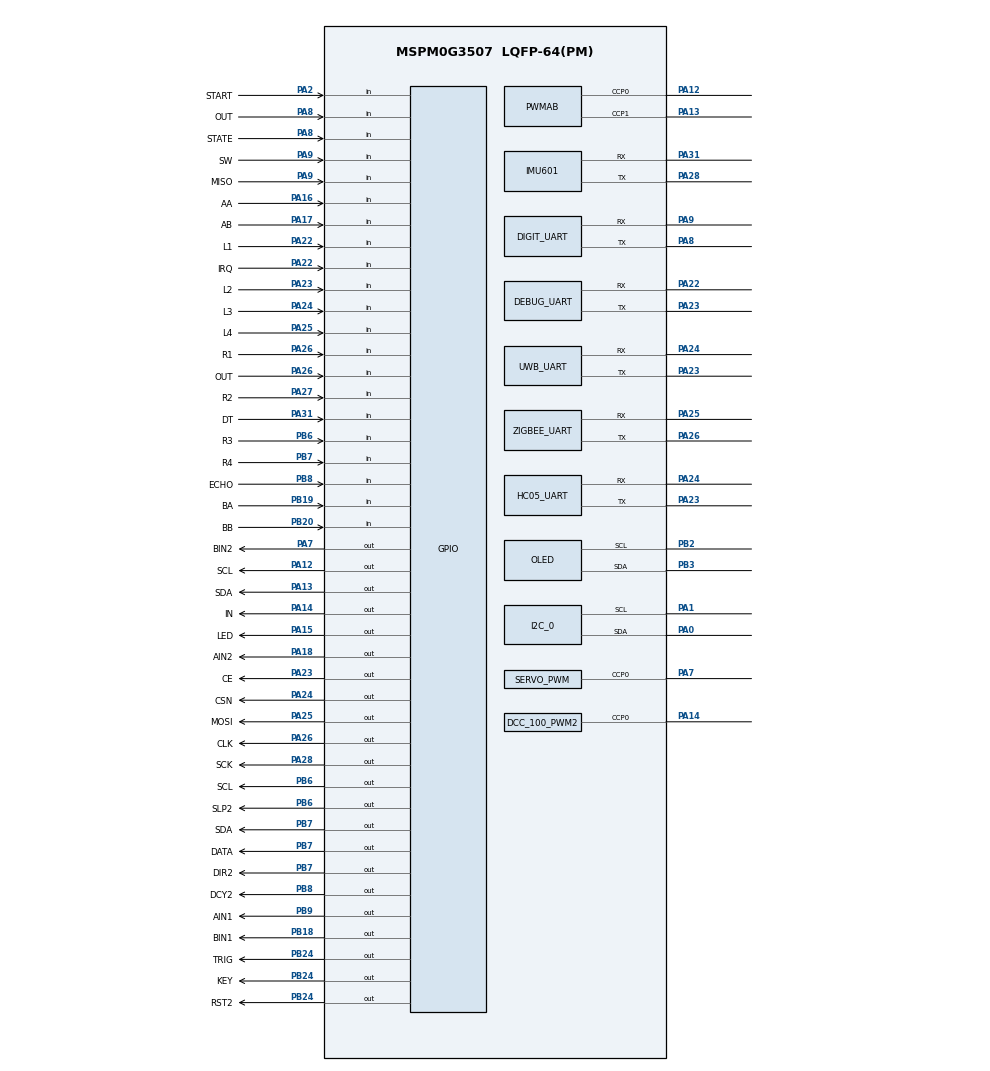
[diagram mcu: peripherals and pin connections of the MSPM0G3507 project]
/**
 * firstep mspm0 母版默认外设布局（地猛星 LCKFB-DMX 开发板，模块库默认引脚方案，
 * 编译闭环用；2026-08-14 地猛星化，工单 mspm0-master-dimx/01）。
 * 实例名/宏名与模块库代码一一对应（PWMAB/DC_MOTOR/IMU601/OLED/NTB/MOTOR_PID/
 * HUIDU/KEY/LED_BEEP/STEP_MOTOR/DCC_100_PWM2/I2C_0）；实际接线不同时改引脚名
 * 即可，实例名与宏名勿动。
 * 引脚方案（除 PB4/PB5 外全部在地猛星 2×20 排针上）：
 *   motor：PWMAB C0/C1→PA12/PA13、DC_MOTOR AIN1=PB9 AIN2=PA18 BIN1=PB18
 *   BIN2=PA7、编码器 AA=PA16 AB=PA17 BA=PB19 BB=PB20
 *   HUIDU：PA22-27/PB4/PB5（R3/R4 的 PB4/PB5 为 LaunchPad 遗留，地猛星未引出）
 *   KEY：PA2（板载 ROSC 偏置 100k 到地，按键与上拉共用此脚）
 *   LED_BEEP：PA15；IR_BEAM：PA8（红外对射 OUT，ir_beam 模块；与
 *   DIGIT_UART 默认重叠，同选时经引脚绑定消解）；IMU601：UART0 =
 *   PA28(TX)/PA31(RX)（板载 CH340E 占
 *   UART0 的 PA10/PA11，勿用）；DIGIT_UART：UART1 = PA8(TX)/PA9(RX)（K230 串口）
 *   OLED：I2C1 = PB3(SDA)/PB2(SCL)；I2C_0：I2C0 = PA0(SDA)/PA1(SCL)（MPU6050，
 *   复用板载 LED 脚——总线空闲高电平 LED 不亮，通信期间微闪；PA1 板载 4.7k 上拉，
 *   PA0 上拉未焊 R12，靠 MPU 板自带）
 *   STEP_MOTOR：RST2/SLP2/DIR2/DCY2 = PB24/PB6/PB7/PB8（全 GPIOB，
 *   STEP_MOTOR_PORT 整组 GPIOB）；DCC_100_PWM2：TIMG12 C0 = PA14（板上经
 *   LED2+15k 到地，PWM 输出时 LED 微亮，可忽略）
 *   JOYSTICK：SW = PA9（摇杆按键，上拉输入低有效；与 DIGIT_UART RX 默认
 *   重叠——手动摇杆与 K230 视觉同选概率最低，同选时经引脚绑定消解）；
 *   ADC12_0 四通道：MEM0 = PA24(A0_3) 归 adc 模块（us016 共读同槽），
 *   MEM1 = PA26(A0_1) / MEM2 = PA25(A0_2) 归 joystick 摇杆 X/Y（与
 *   ZIGBEE_UART 默认重叠——手动摇杆与无线身份/信标同选概率最低，同选时
 *   经引脚绑定消解；多 MEM 必须 sequence 模式，2026-09-05 SysConfig CLI
 *   实证），MEM3 = PA27(A0_0) 归 ir_distance（与 HUIDU R2 重叠——红外
 *   测距与灰度巡线同选概率最低）
 *   HC05：HC05_UART = UART2 共享（9600——HC05 出厂默认波特率，与 DEBUG+UWB
 *   同外设；默认 PA23/PA24 与 UWB 同脚——蓝牙与 UWB 链路互替、同选概率
 *   最低，同选时经引脚绑定换实例消解）；STATE = PA8 输入（连接状态，
 *   高有效；与 DIGIT_UART TX/IR_BEAM OUT 重叠——蓝牙与 K230 视觉/红外对射
 *   链路互替）、KEY = PB24 输出（AT 模式切换，与 STEP_MOTOR RST2/SR04 TRIG
 *   重叠——AT 切换不常用，同选经引脚绑定消解）
 *   NRF24L01：软 SPI 6 脚全 GPIOA（CLK=PA26/MOSI=PA25/MISO=PA9/
 *   CSN=PA24/CE=PA23/IRQ=PA22，单 NRF24L01_PORT 宏）——与 ZIGBEE_UART/
 *   UWB/DEBUG_UART/HUIDU 巡线/joystick/adc/DIGIT 默认重叠：NRF 与其它无线
 *   链路互替、同选概率最低，同选时经引脚绑定消解；IRQ 输入不配中断（GPIO
 *   中断只有 GROUP1 一路且被 motor 编码器独占，第二个 GROUP1_IRQHandler 会
 *   链接期冲突——按手册轮询方式接收，见 nrf24l01 模块注释）
 *   IR_REMOTE：OUT = PA26 输入（红外接收头，NEC 忙等解码不占 TIMER；
 *   与 ZIGBEE_TX/joystick X/NRF24L01 CLK 重叠——红外与其它无线/手动输入
 *   互替、同选概率最低，同选时经引脚绑定消解；主循环轮询解码，不注册
 *   GPIO 中断，原因同 NRF24L01）
 * 板上固定占用：CH340E PA10/PA11、Flash PB14-17、晶振 PA3-6、板载 LED PA0/PA1、
 * VREF- PA21 直连地、BSL PA18（47k 到 BSL 排针）、SWD PA19/PA20（独立 DEBUG 排针，
 * 用户实物未在 2×20P 上找到 A19/A20）、NRST。2026-08-20 用户实物核验：芯片丝印
 * 可见 42WG4 / ABDL，外周为 48 脚，2×20P 排针分布正确，PA13/PA14 在排针上可用。
 * TI 封装命名中 LQFP(PT)=48 脚、LQFP(PM)=64 脚；当前 SysConfig 仍沿用可工作的
 * LQFP-64(PM) / LP-MSPM0G3507 模型，不以此反推实物脚数。实际地猛星 2×20P
 * 引出范围由 mspm0-dimx 板定义约束，PB4/PB5 为 LaunchPad 遗留模型脚、不在 2×20P 上。
 */
//@cliArgs --device "MSPM0G350X" --package "LQFP-64(PM)" --part "Default"
//@v2CliArgs --device "MSPM0G3507" --package "LQFP-64(PM)"
// @cliArgs --board /ti/boards/LP_MSPM0G3507 --rtos nortos

/**
 * Import the modules used in this configuration.
 */
const PWM     = scripting.addModule("/ti/driverlib/PWM", {}, false);
const PWMAB   = PWM.addInstance();
const DCC_100_PWM2 = PWM.addInstance();
// 舵机（servo 模块：50Hz/20ms 周期，0.5-2.5ms 脉宽映射 0-180°；周期由
// servo_init 按 SERVO_PWM_INST_CLK_FREQ 运行时配置，此处初值仅保证可编译）
const SERVO_PWM = PWM.addInstance();
SERVO_PWM.$name                      = "SERVO_PWM";
SERVO_PWM.clockPrescale              = 1;
SERVO_PWM.timerCount                 = 65535;
SERVO_PWM.peripheral.$assign         = "TIMG8";
SERVO_PWM.peripheral.ccp0Pin.$assign = "PA7";
const TIMER   = scripting.addModule("/ti/driverlib/TIMER", {}, false);
const MOTOR_PID = TIMER.addInstance();
const NTB     = TIMER.addInstance();
const GPIO    = scripting.addModule("/ti/driverlib/GPIO", {}, false);
const DC_MOTOR = GPIO.addInstance();
const HUIDU   = GPIO.addInstance();
const KEY     = GPIO.addInstance();
const WS2812 = GPIO.addInstance();
const HX711 = GPIO.addInstance();
const AHT10 = GPIO.addInstance();
const SR04 = GPIO.addInstance();
const JOYSTICK = GPIO.addInstance();
const HC05 = GPIO.addInstance();
const NRF24L01 = GPIO.addInstance();
const IR_REMOTE = GPIO.addInstance();
const LED_BEEP = GPIO.addInstance();
const STEP_MOTOR = GPIO.addInstance();
const IR_BEAM = GPIO.addInstance();
const UART    = scripting.addModule("/ti/driverlib/UART", {}, false);
const IMU601  = UART.addInstance();
const I2C     = scripting.addModule("/ti/driverlib/I2C", {}, false);
const OLED    = I2C.addInstance();
const I2C_0   = I2C.addInstance();
const SYSCTL  = scripting.addModule("/ti/driverlib/SYSCTL");

/**
 * Write custom configuration values to the imported modules.
 */

// 电机 PWM：双通道 C0/C1（TB6612 左/右 PWM 输入）
PWMAB.$name                      = "PWMAB";
PWMAB.clockPrescale              = 256;
PWMAB.timerCount                 = 2000;
PWMAB.peripheral.$assign         = "TIMG0";
PWMAB.peripheral.ccp0Pin.$assign = "PA12";
PWMAB.peripheral.ccp1Pin.$assign = "PA13";
PWMAB.PWM_CHANNEL_0.$name        = "ti_driverlib_pwm_PWMTimerCC0";
PWMAB.PWM_CHANNEL_0.dutyCycle    = 0;
PWMAB.PWM_CHANNEL_1.$name        = "ti_driverlib_pwm_PWMTimerCC1";
PWMAB.PWM_CHANNEL_1.dutyCycle    = 0;

// 步进电机脉冲输出（step_motor 模块：DCC_100_PWM2_INST，TIMG12 32 位定时器，
// clockPrescale 必须为 1——step_set_speed 按 INST_CLK_FREQ/频率 直算周期；C0 = PA14）
DCC_100_PWM2.$name              = "DCC_100_PWM2";
DCC_100_PWM2.clockPrescale      = 1;
DCC_100_PWM2.timerCount         = 65535;
DCC_100_PWM2.peripheral.$assign = "TIMG12";
DCC_100_PWM2.peripheral.ccp0Pin.$assign = "PA14";
DCC_100_PWM2.PWM_CHANNEL_0.$name        = "ti_driverlib_pwm_DCC100_CC0";
DCC_100_PWM2.PWM_CHANNEL_0.dutyCycle    = 50;

// 电机 PID 调度定时器（10ms 周期中断，pid 模块用；编译闭环只需宏存在）
MOTOR_PID.$name              = "MOTOR_PID";
MOTOR_PID.profile            = "Basic_Periodic";
MOTOR_PID.peripheral.$assign = "TIMG6";

// 计程定时器（ntb_time 模块读计数）
NTB.$name              = "NTB";
NTB.profile            = "Basic_Periodic";
NTB.peripheral.$assign = "TIMG7";

// 超声波 TRIG/ECHO（sr04 模块：TRIG 输出触发 / ECHO 输入回波；测宽用
// CPU 忙等计数，不占 TIMER 外设——地猛星 SysConfig TIMER 实例仅暴露
// TIMG0/6/7/8/12（已被 motor/pid/ntb_time/servo/step_motor 全占，没有
// 新定时器可加）。默认 TRIG=PB24（与 STEP_MOTOR RST2 重叠）、ECHO=PB8
// （与 STEP_MOTOR DCY2 重叠）——测距与步进同选概率最低，同选时经引脚
// 绑定消解）
SR04.$name = "SR04";
SR04.associatedPins.create(2);
SR04.associatedPins[0].$name        = "TRIG";
SR04.associatedPins[0].direction    = "OUTPUT";
SR04.associatedPins[0].initialValue = "CLEARED";
SR04.associatedPins[0].pin.$assign  = "PB24";
SR04.associatedPins[1].$name        = "ECHO";
SR04.associatedPins[1].direction    = "INPUT";
SR04.associatedPins[1].pin.$assign  = "PB8";

// 电机方向/使能 + 编码器中断（key 模块 GROUP1_IRQHandler 消费 IIDX）
DC_MOTOR.$name = "DC_MOTOR";
DC_MOTOR.associatedPins.create(8);
DC_MOTOR.associatedPins[0].$name        = "AIN1";
DC_MOTOR.associatedPins[0].direction    = "OUTPUT";
DC_MOTOR.associatedPins[0].initialValue = "CLEARED";
DC_MOTOR.associatedPins[0].pin.$assign  = "PB9";
DC_MOTOR.associatedPins[1].$name        = "AIN2";
DC_MOTOR.associatedPins[1].direction    = "OUTPUT";
DC_MOTOR.associatedPins[1].initialValue = "CLEARED";
DC_MOTOR.associatedPins[1].pin.$assign  = "PA18";
DC_MOTOR.associatedPins[2].$name        = "BIN1";
DC_MOTOR.associatedPins[2].direction    = "OUTPUT";
DC_MOTOR.associatedPins[2].initialValue = "CLEARED";
DC_MOTOR.associatedPins[2].pin.$assign  = "PB18";
DC_MOTOR.associatedPins[3].$name        = "BIN2";
DC_MOTOR.associatedPins[3].direction    = "OUTPUT";
DC_MOTOR.associatedPins[3].initialValue = "CLEARED";
DC_MOTOR.associatedPins[3].pin.$assign  = "PA7";
DC_MOTOR.associatedPins[4].$name        = "AA";
DC_MOTOR.associatedPins[4].direction    = "INPUT";
DC_MOTOR.associatedPins[4].interruptEn  = true;
DC_MOTOR.associatedPins[4].polarity     = "RISE_FALL";
DC_MOTOR.associatedPins[4].pin.$assign  = "PA16";
DC_MOTOR.associatedPins[5].$name        = "AB";
DC_MOTOR.associatedPins[5].direction    = "INPUT";
DC_MOTOR.associatedPins[5].interruptEn  = true;
DC_MOTOR.associatedPins[5].polarity     = "RISE_FALL";
DC_MOTOR.associatedPins[5].pin.$assign  = "PA17";
DC_MOTOR.associatedPins[6].$name        = "BA";
DC_MOTOR.associatedPins[6].direction    = "INPUT";
DC_MOTOR.associatedPins[6].interruptEn  = true;
DC_MOTOR.associatedPins[6].polarity     = "RISE_FALL";
DC_MOTOR.associatedPins[6].pin.$assign  = "PB19";
DC_MOTOR.associatedPins[7].$name        = "BB";
DC_MOTOR.associatedPins[7].direction    = "INPUT";
DC_MOTOR.associatedPins[7].interruptEn  = true;
DC_MOTOR.associatedPins[7].polarity     = "RISE_FALL";
DC_MOTOR.associatedPins[7].pin.$assign  = "PB20";

// 8 路灰度循线输入（引脚空闲位，按实际接线改）
HUIDU.$name = "HUIDU";
HUIDU.associatedPins.create(8);
HUIDU.associatedPins[0].$name       = "L1";
HUIDU.associatedPins[0].direction   = "INPUT";
HUIDU.associatedPins[0].pin.$assign = "PA22";
HUIDU.associatedPins[1].$name       = "L2";
HUIDU.associatedPins[1].direction   = "INPUT";
HUIDU.associatedPins[1].pin.$assign = "PA23";
HUIDU.associatedPins[2].$name       = "L3";
HUIDU.associatedPins[2].direction   = "INPUT";
HUIDU.associatedPins[2].pin.$assign = "PA24";
HUIDU.associatedPins[3].$name       = "L4";
HUIDU.associatedPins[3].direction   = "INPUT";
HUIDU.associatedPins[3].pin.$assign = "PA25";
HUIDU.associatedPins[4].$name       = "R1";
HUIDU.associatedPins[4].direction   = "INPUT";
HUIDU.associatedPins[4].pin.$assign = "PA26";
HUIDU.associatedPins[5].$name       = "R2";
HUIDU.associatedPins[5].direction   = "INPUT";
HUIDU.associatedPins[5].pin.$assign = "PA27";
HUIDU.associatedPins[6].$name       = "R3";
HUIDU.associatedPins[6].direction   = "INPUT";
HUIDU.associatedPins[6].pin.$assign = "PB6";
HUIDU.associatedPins[7].$name       = "R4";
HUIDU.associatedPins[7].direction   = "INPUT";
HUIDU.associatedPins[7].pin.$assign = "PB7";

// 启动按键输入（实例名 KEY → KEY_PORT 宏；引脚名 START → KEY_START_PIN）
KEY.$name = "KEY";
KEY.associatedPins.create(1);
KEY.associatedPins[0].$name       = "START";
KEY.associatedPins[0].direction   = "INPUT";
KEY.associatedPins[0].pin.$assign = "PA2";

// 红外对射传感器输入（ir_beam 模块：实例名 IR_BEAM → IR_BEAM_PORT 宏；
// 引脚名 OUT → IR_BEAM_OUT_PIN；默认 PA8——仅与 DIGIT_UART 默认重叠，
// 同选时经引脚绑定消解；内部上拉 = 遮挡（开集输出截止）时由电阻钳到高，
// 无遮挡 = 接收管导通拉低）
IR_BEAM.$name = "IR_BEAM";
IR_BEAM.associatedPins.create(1);
IR_BEAM.associatedPins[0].$name            = "OUT";
IR_BEAM.associatedPins[0].direction        = "INPUT";
IR_BEAM.associatedPins[0].internalResistor = "PULL_UP";
IR_BEAM.associatedPins[0].pin.$assign      = "PA8";

// WS2812 幻彩灯带数据脚（ws2812 模块：单 GPIO 强推挽输出，位操作时序；
// 默认 PA14——与 DCC_100_PWM2（step_motor 脉冲）默认重叠，同选时经引脚
// 绑定消解。地猛星 2×20 排针 31 个 IO 已被母版默认布局全占，新模块默认
// 脚按「与同选概率最低者重叠」分配，IR_BEAM/PA8 先例）
WS2812.$name = "WS2812";
WS2812.associatedPins.create(1);
WS2812.associatedPins[0].$name        = "IN";
WS2812.associatedPins[0].direction    = "OUTPUT";
WS2812.associatedPins[0].initialValue = "CLEARED";
WS2812.associatedPins[0].pin.$assign  = "PA14";

// HX711 称重（hx711 模块：SCK 输出 / DT 输入（片上拉，空闲高 = 未就绪，
// 数据就绪拉低）。默认 SCK=PA28（与 IMU601 TX 重叠）、DT=PA31（与 IMU601
// RX 重叠）——称重与串口陀螺仪同为「姿态/力」低频组合，同选概率最低；
// 同选时经引脚绑定消解）
HX711.$name = "HX711";
HX711.associatedPins.create(2);
HX711.associatedPins[0].$name        = "SCK";
HX711.associatedPins[0].direction    = "OUTPUT";
HX711.associatedPins[0].initialValue = "CLEARED";
HX711.associatedPins[0].pin.$assign  = "PA28";
HX711.associatedPins[1].$name        = "DT";
HX711.associatedPins[1].direction    = "INPUT";
HX711.associatedPins[1].internalResistor = "PULL_UP";
HX711.associatedPins[1].pin.$assign  = "PA31";

// AHT10 温湿度软 I2C（aht10 模块：SCL 输出 / SDA 双向运行时切换；
// 位操作不占硬件 I2C 外设。默认 SCL=PB6（与 STEP_MOTOR SLP2 / HUIDU R3
// 重叠）、SDA=PB7（与 STEP_MOTOR DIR2 / HUIDU R4 重叠）——温湿度与步进/
// 巡线同选概率最低，同选时经引脚绑定消解；软 I2C 需板上/模块自带上拉）
AHT10.$name = "AHT10";
AHT10.associatedPins.create(2);
AHT10.associatedPins[0].$name        = "SCL";
AHT10.associatedPins[0].direction    = "OUTPUT";
AHT10.associatedPins[0].initialValue = "CLEARED";
AHT10.associatedPins[0].pin.$assign  = "PB6";
AHT10.associatedPins[1].$name        = "SDA";
AHT10.associatedPins[1].direction    = "OUTPUT";
AHT10.associatedPins[1].initialValue = "CLEARED";
AHT10.associatedPins[1].pin.$assign  = "PB7";

// DHT11 单总线温湿度（dht11 模块：DATA 双向——输出起始信号/释放总线、
// 输入采样响应与 40bit 数据位，方向运行时切换（照 AHT10_SDA 先例）；
// 位时序 CPU 忙等 + delay 模块换算，不占 TIMER。默认 DATA=PB7——与
// AHT10 SDA（温湿度互替、同选概率最低）/STEP_MOTOR DIR2/HUIDU R4
// 重叠（温湿度与步进/巡线同选概率最低，AHT10 先例），同选时经引脚绑定消解）
const DHT11 = GPIO.addInstance();
DHT11.$name = "DHT11";
DHT11.associatedPins.create(1);
DHT11.associatedPins[0].$name        = "DATA";
DHT11.associatedPins[0].direction    = "OUTPUT";
DHT11.associatedPins[0].initialValue = "SET";
DHT11.associatedPins[0].pin.$assign  = "PB7";

// BH1750 光照度软 I2C（bh1750 模块：SCL 输出 / SDA 双向运行时切换；
// 位操作不占硬件 I2C 外设，照 AHT10 先例。默认 SCL=PA12 / SDA=PA13——
// 与 PWMAB C0/C1（motor 双路 PWM）重叠：光照度监测/台灯类与双电机驱动
// 同选概率最低（故意不叠 AHT10 的 PB6/PB7——温湿度+光照=环境监测站常见
// 组合），同选时经引脚绑定消解；软 I2C 需板上/模块自带上拉）
const BH1750 = GPIO.addInstance();
BH1750.$name = "BH1750";
BH1750.associatedPins.create(2);
BH1750.associatedPins[0].$name        = "SCL";
BH1750.associatedPins[0].direction    = "OUTPUT";
BH1750.associatedPins[0].initialValue = "CLEARED";
BH1750.associatedPins[0].pin.$assign  = "PA12";
BH1750.associatedPins[1].$name        = "SDA";
BH1750.associatedPins[1].direction    = "OUTPUT";
BH1750.associatedPins[1].initialValue = "CLEARED";
BH1750.associatedPins[1].pin.$assign  = "PA13";

// 双轴摇杆按键（joystick 模块：SW 输入上拉低有效；实例名 JOYSTICK →
// JOYSTICK_PORT 宏；引脚名 SW → JOYSTICK_SW_PIN；默认 PA9——仅与
// DIGIT_UART RX 默认重叠（K230 视觉串口），同选时经引脚绑定消解。
// X/Y 两轴走 ADC12_0 MEM1/MEM2（见 ADC 段），SW 独立 GPIO）
JOYSTICK.$name = "JOYSTICK";
JOYSTICK.associatedPins.create(1);
JOYSTICK.associatedPins[0].$name            = "SW";
JOYSTICK.associatedPins[0].direction        = "INPUT";
JOYSTICK.associatedPins[0].internalResistor = "PULL_UP";
JOYSTICK.associatedPins[0].pin.$assign  = "PA9";

// HC05 蓝牙（hc05 模块：STATE 输入 = 连接状态指示（模块 STATE 脚高 = 手机
// 已连接；默认 PA8——与 DIGIT_UART TX / IR_BEAM OUT 默认重叠：K230 视觉/
// 红外对射与蓝牙链路互替，同选时经引脚绑定消解）；KEY 输出 = AT 模式切换
// 按键（KEY 高 + 重上电 = AT 命令模式；默认 PB24——与 STEP_MOTOR RST2 /
// SR04 TRIG 重叠，AT 切换不常用，同选时经引脚绑定消解））
HC05.$name = "HC05";
HC05.associatedPins.create(2);
HC05.associatedPins[0].$name            = "STATE";
HC05.associatedPins[0].direction        = "INPUT";
HC05.associatedPins[0].pin.$assign      = "PA8";
HC05.associatedPins[1].$name            = "KEY";
HC05.associatedPins[1].direction        = "OUTPUT";
HC05.associatedPins[1].initialValue     = "CLEARED";
HC05.associatedPins[1].pin.$assign      = "PB24";

// NRF24L01 2.4G 无线（nrf24l01 模块：软 SPI 位操作 6 脚——CLK/MOSI/CSN/CE
// 输出 + MISO/IRQ 输入；IRQ 输入不配中断（GPIO 中断只有 GROUP1 一路且被
// motor 编码器独占——NRF+电机是双车标配组合，定义第二个 GROUP1_IRQHandler
// 会链接期冲突，按手册轮询方式接收）。默认全 GPIOA 单口：CLK=PA26/MOSI=PA25/
// MISO=PA9/CSN=PA24/CE=PA23/IRQ=PA22——与 ZIGBEE_UART（PA26/PA25）、
// UWB/DEBUG_UART（PA23/PA24/PA22）、HUIDU 巡线（PA22-26）、joystick X/Y、
// adc、DIGIT_UART（PA9）默认重叠：NRF 与其它无线/巡线/手动输入互替、同选
// 概率最低，同选时经引脚绑定消解）
NRF24L01.$name = "NRF24L01";
NRF24L01.associatedPins.create(6);
NRF24L01.associatedPins[0].$name        = "CLK";
NRF24L01.associatedPins[0].direction    = "OUTPUT";
NRF24L01.associatedPins[0].initialValue = "CLEARED";
NRF24L01.associatedPins[0].pin.$assign  = "PA26";
NRF24L01.associatedPins[1].$name        = "MOSI";
NRF24L01.associatedPins[1].direction    = "OUTPUT";
NRF24L01.associatedPins[1].initialValue = "CLEARED";
NRF24L01.associatedPins[1].pin.$assign  = "PA25";
NRF24L01.associatedPins[2].$name        = "MISO";
NRF24L01.associatedPins[2].direction    = "INPUT";
NRF24L01.associatedPins[2].pin.$assign  = "PA9";
NRF24L01.associatedPins[3].$name        = "CSN";
NRF24L01.associatedPins[3].direction    = "OUTPUT";
NRF24L01.associatedPins[3].initialValue = "SET";
NRF24L01.associatedPins[3].pin.$assign  = "PA24";
NRF24L01.associatedPins[4].$name        = "CE";
NRF24L01.associatedPins[4].direction    = "OUTPUT";
NRF24L01.associatedPins[4].initialValue = "CLEARED";
NRF24L01.associatedPins[4].pin.$assign  = "PA23";
NRF24L01.associatedPins[5].$name        = "IRQ";
NRF24L01.associatedPins[5].direction    = "INPUT";
NRF24L01.associatedPins[5].pin.$assign  = "PA22";

// 红外遥控接收（ir_remote 模块：OUT 输入（接收头输出直接接 GPIO，上拉 = 无
// 信号高电平、有信号拉低）；NEC 解码用 CPU 忙等采样（delay 模块 20us 步进），
// 不占 TIMER（TIMG 全占，sr04 先例）；主循环轮询解码、不注册 GPIO 中断
// （GROUP1 只有一路且被 motor 编码器独占——红外+电机是经典组合）。默认
// PA26——与 ZIGBEE_TX/joystick X/NRF24L01 CLK 默认重叠（红外与其它无线/
// 手动输入互替、同选概率最低），同选时经引脚绑定消解）
IR_REMOTE.$name = "IR_REMOTE";
IR_REMOTE.associatedPins.create(1);
IR_REMOTE.associatedPins[0].$name            = "OUT";
IR_REMOTE.associatedPins[0].direction        = "INPUT";
IR_REMOTE.associatedPins[0].internalResistor = "PULL_UP";
IR_REMOTE.associatedPins[0].pin.$assign      = "PA26";

// LED/蜂鸣器输出（PA15；原 LaunchPad 值 PA3 = 32.768k 晶振脚，地猛星排针未引出）
LED_BEEP.$name = "LED_BEEP";
LED_BEEP.associatedPins.create(1);
LED_BEEP.associatedPins[0].$name        = "LED";
LED_BEEP.associatedPins[0].direction    = "OUTPUT";
LED_BEEP.associatedPins[0].initialValue = "CLEARED";
LED_BEEP.associatedPins[0].pin.$assign  = "PA15";

// 步进电机方向/使能（step_motor 模块：宏 STEP_MOTOR_RST2/SLP2/DIR2/DCY2_PIN，
// 四脚同 GPIOB → STEP_MOTOR_PORT = GPIOB；RST2/SLP2 空闲高有效，init 置高）
STEP_MOTOR.$name = "STEP_MOTOR";
STEP_MOTOR.associatedPins.create(4);
STEP_MOTOR.associatedPins[0].$name        = "RST2";
STEP_MOTOR.associatedPins[0].direction    = "OUTPUT";
STEP_MOTOR.associatedPins[0].initialValue = "SET";
STEP_MOTOR.associatedPins[0].pin.$assign  = "PB24";
STEP_MOTOR.associatedPins[1].$name        = "SLP2";
STEP_MOTOR.associatedPins[1].direction    = "OUTPUT";
STEP_MOTOR.associatedPins[1].initialValue = "SET";
STEP_MOTOR.associatedPins[1].pin.$assign  = "PB6";
STEP_MOTOR.associatedPins[2].$name        = "DIR2";
STEP_MOTOR.associatedPins[2].direction    = "OUTPUT";
STEP_MOTOR.associatedPins[2].initialValue = "CLEARED";
STEP_MOTOR.associatedPins[2].pin.$assign  = "PB7";
STEP_MOTOR.associatedPins[3].$name        = "DCY2";
STEP_MOTOR.associatedPins[3].direction    = "OUTPUT";
STEP_MOTOR.associatedPins[3].initialValue = "CLEARED";
STEP_MOTOR.associatedPins[3].pin.$assign  = "PB8";

// IMU 串口（RX 中断；UART0 = PA28(TX)/PA31(RX)——板载 CH340E 占用 UART0 默认脚
// PA10/PA11，勿用；imu_uart 模块接线注释同步此值）
IMU601.$name             = "IMU601";
IMU601.profile           = "CONFIG_PROFILE_1";
IMU601.peripheral.$assign = "UART0";
IMU601.uartClkSrc        = "BUSCLK";
IMU601.ovsRate           = "16";
IMU601.targetBaudRate    = 115200;
IMU601.enableInternalLoopback = false;
IMU601.enabledInterrupts = ["RX"];
IMU601.enableFIFO        = false;
IMU601.peripheral.rxPin.$assign = "PA31";
IMU601.peripheral.txPin.$assign = "PA28";

// K230 视觉串口（digit_uart/coord_detect 模块用，RX 中断；PA8/PA9 = UART1）
const DIGIT_UART = UART.addInstance();
DIGIT_UART.$name             = "DIGIT_UART";
DIGIT_UART.profile           = "CONFIG_PROFILE_1";
DIGIT_UART.peripheral.$assign = "UART1";
DIGIT_UART.uartClkSrc        = "BUSCLK";
DIGIT_UART.ovsRate           = "16";
DIGIT_UART.targetBaudRate    = 115200;
DIGIT_UART.enableInternalLoopback = false;
DIGIT_UART.enabledInterrupts = ["RX"];
DIGIT_UART.enableFIFO        = false;
DIGIT_UART.peripheral.rxPin.$assign = "PA9";
DIGIT_UART.peripheral.txPin.$assign = "PA8";

// 调试串口（debug_uart 模块用，RX 中断；UART2 = PA23(TX)/PA22(RX)。
// 与 UWB_UART 默认同 UART2——两模块同选时经引脚绑定换实例消解；
// PA23/PA22 与 HUIDU L2/L1 默认重叠，同选时改绑消解）
const DEBUG_UART = UART.addInstance();
DEBUG_UART.$name             = "DEBUG_UART";
DEBUG_UART.profile           = "CONFIG_PROFILE_1";
DEBUG_UART.peripheral.$assign = "UART2";
DEBUG_UART.uartClkSrc        = "BUSCLK";
DEBUG_UART.ovsRate           = "16";
DEBUG_UART.targetBaudRate    = 115200;
DEBUG_UART.enableInternalLoopback = false;
DEBUG_UART.enabledInterrupts = ["RX"];
DEBUG_UART.enableFIFO        = false;
DEBUG_UART.peripheral.rxPin.$assign = "PA22";
DEBUG_UART.peripheral.txPin.$assign = "PA23";

// UWB 定位串口（uwb_uart 模块用，RX 中断；UART2 = PA23(TX)/PA24(RX)。
// PA23/PA24 与 HUIDU L2/L3 默认重叠——两模块同选时经引脚绑定消解）
const UWB_UART = UART.addInstance();
UWB_UART.$name             = "UWB_UART";
UWB_UART.profile           = "CONFIG_PROFILE_1";
UWB_UART.peripheral.$assign = "UART2";
UWB_UART.uartClkSrc        = "BUSCLK";
UWB_UART.ovsRate           = "16";
UWB_UART.targetBaudRate    = 115200;
UWB_UART.enableInternalLoopback = false;
UWB_UART.enabledInterrupts = ["RX"];
UWB_UART.enableFIFO        = false;
UWB_UART.peripheral.rxPin.$assign = "PA24";
UWB_UART.peripheral.txPin.$assign = "PA23";

// Zigbee DL-20 串口（zigbee_uart 接收 / zigbee_uart_key 发送共享，
// RX 中断；UART3 = PA26(TX)/PA25(RX)。PA26/PA25 与 HUIDU R2/R3 默认
// 重叠——同选时经引脚绑定消解）
const ZIGBEE_UART = UART.addInstance();
ZIGBEE_UART.$name             = "ZIGBEE_UART";
ZIGBEE_UART.profile           = "CONFIG_PROFILE_1";
ZIGBEE_UART.peripheral.$assign = "UART3";
ZIGBEE_UART.uartClkSrc        = "BUSCLK";
ZIGBEE_UART.ovsRate           = "16";
ZIGBEE_UART.targetBaudRate    = 115200;
ZIGBEE_UART.enableInternalLoopback = false;
ZIGBEE_UART.enabledInterrupts = ["RX"];
ZIGBEE_UART.enableFIFO        = false;
ZIGBEE_UART.peripheral.rxPin.$assign = "PA25";
ZIGBEE_UART.peripheral.txPin.$assign = "PA26";

// HC05 蓝牙串口（hc05 模块：9600 8N1 透传——HC05 模块出厂默认波特率，与
// 其余 UART 实例 115200 独立无冲突；RX 中断 + FIFO 关闭；与 DEBUG_UART/
// UWB_UART 默认同 UART2 外设——两模块同选时经引脚绑定换实例消解；默认
// TX=PA23/RX=PA24 与 UWB_UART 同脚：蓝牙手机遥控与 UWB 定位链路互替、
// 同选概率最低，同选时经引脚绑定消解）
const HC05_UART = UART.addInstance();
HC05_UART.$name             = "HC05_UART";
HC05_UART.profile           = "CONFIG_PROFILE_1";
HC05_UART.peripheral.$assign = "UART2";
HC05_UART.uartClkSrc        = "BUSCLK";
HC05_UART.ovsRate           = "16";
HC05_UART.targetBaudRate    = 9600;
HC05_UART.enableInternalLoopback = false;
HC05_UART.enabledInterrupts = ["RX"];
HC05_UART.enableFIFO        = false;
HC05_UART.peripheral.rxPin.$assign = "PA24";
HC05_UART.peripheral.txPin.$assign = "PA23";

// OLED（I2C 控制器）
OLED.$name                         = "OLED";
OLED.basicEnableController         = true;
OLED.basicControllerBusSpeed       = 400000;
OLED.intController                 = ["NACK", "TX_DONE"];
OLED.advAnalogGlitchFilter         = "DISABLED";
OLED.peripheral.$assign            = "I2C1";
OLED.peripheral.sdaPin.$assign     = "PB3";
OLED.peripheral.sclPin.$assign     = "PB2";

// MPU6050 姿态传感器（ml_mpu6050 模块：I2C_0_INST，轮询控制器模式；
// I2C0 = PA0(SDA)/PA1(SCL) 复用板载 LED 脚，通信期间 LED 微闪——地猛星 I2C0 的
// 另一组 PA28/PA31 已给 IMU601 UART0；PA1 板载 4.7k 上拉，PA0 上拉未焊 R12、
// 依赖 MPU6050 模块板自带）
I2C_0.$name                     = "I2C_0";
I2C_0.basicEnableController     = true;
I2C_0.basicControllerBusSpeed   = 400000;
I2C_0.peripheral.$assign        = "I2C0";
I2C_0.peripheral.sdaPin.$assign = "PA0";
I2C_0.peripheral.sclPin.$assign = "PA1";

// adc 模块 + 摇杆 + 模拟量测距共享 ADC12_0（b1-adc-servo/01 +
// wiki-modules-batch1/01 + wiki-modules-batch2/02/04：
// MEM0=PA24/A0_3 归 adc（us016 薄封装共读同槽），MEM1=PA26/A0_1、
// MEM2=PA25/A0_2 归 joystick X/Y，MEM3=PA27/A0_0 归 ir_distance 红外测距
// （手册原脚）；轮询读取不配中断。多 MEM 必须 sequence 模式（startAdd..
// endAdd = 启用 MEM 集合）——单发模式只启用 startAdd 槽位，adcPin1/2 由此
// 不可用（原注释「槽位不存在」系误判，2026-09-05 SysConfig CLI 实证）
const ADC12   = scripting.addModule("/ti/driverlib/ADC12", {}, false);
const ADC12_0 = ADC12.addInstance();
ADC12_0.$name                      = "ADC12_0";
ADC12_0.sampClkSrc                 = "DL_ADC12_CLOCK_ULPCLK";
ADC12_0.sampClkDiv                 = "DL_ADC12_CLOCK_DIVIDE_8";
ADC12_0.sampleTime0                = "125 us";
ADC12_0.powerDownMode              = "DL_ADC12_POWER_DOWN_MODE_MANUAL";
ADC12_0.adcMem0chansel             = "DL_ADC12_INPUT_CHAN_3";
ADC12_0.adcMem1chansel             = "DL_ADC12_INPUT_CHAN_1";
ADC12_0.adcMem2chansel             = "DL_ADC12_INPUT_CHAN_2";
ADC12_0.adcMem3chansel             = "DL_ADC12_INPUT_CHAN_0";
ADC12_0.samplingOperationMode      = "sequence";
ADC12_0.startAdd                   = 0;
ADC12_0.endAdd                     = 3;
ADC12_0.peripheral.$assign         = "ADC0";
ADC12_0.peripheral.adcPin3.$assign = "PA24";
ADC12_0.peripheral.adcPin1.$assign  = "PA26";
ADC12_0.peripheral.adcPin2.$assign  = "PA25";
ADC12_0.peripheral.adcPin0.$assign = "PA27";
const Board = scripting.addModule("/ti/driverlib/Board", {}, false);
Board.configureUnused = true;

SYSCTL.forceDefaultClkConfig = true;
SYSCTL.clockTreeEn  = true;
